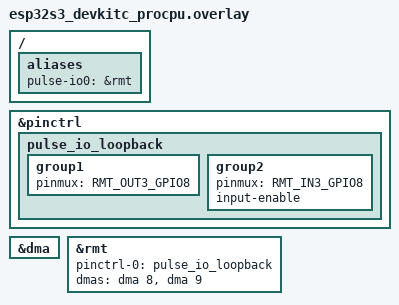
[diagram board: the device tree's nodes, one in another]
/*
 * Copyright (c) 2026 Espressif Systems (Shanghai) Co., Ltd.
 *
 * SPDX-License-Identifier: Apache-2.0
 *
 * Internal loopback on GPIO8 using the DMA capable channels of
 * this board.
 */

&pinctrl {
	pulse_io_loopback: pulse_io_loopback {
		group1 {
			pinmux = <RMT_OUT3_GPIO8>;
		};

		group2 {
			pinmux = <RMT_IN3_GPIO8>;
			input-enable;
		};
	};
};

&dma {
	status = "okay";
};

&rmt {
	pinctrl-0 = <&pulse_io_loopback>;
	pinctrl-names = "default";
	dmas = <&dma 8>, <&dma 9>;
	dma-names = "rx", "tx";
	status = "okay";
};

/ {
	aliases {
		pulse-io0 = &rmt;
	};
};
